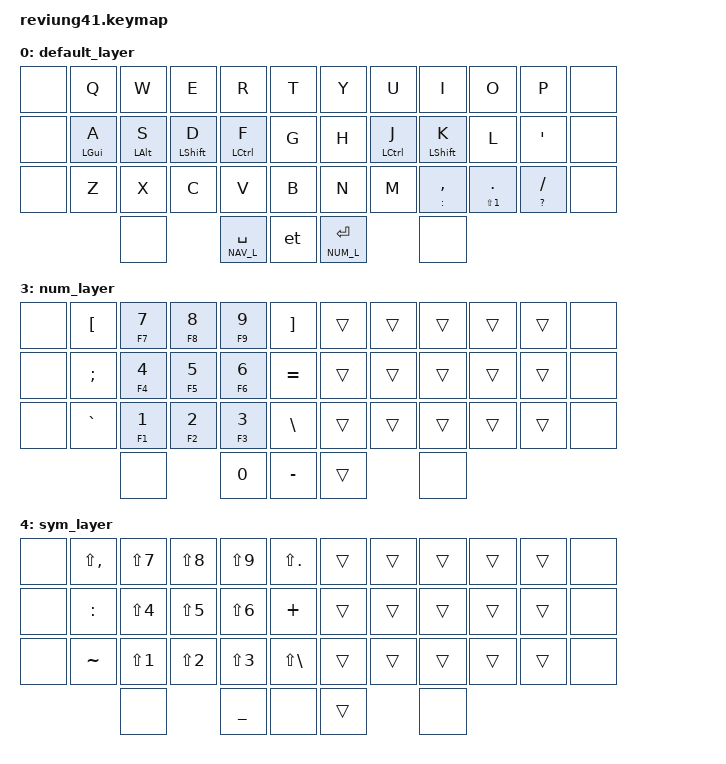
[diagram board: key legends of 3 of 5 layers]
/*
 * Copyright (c) 2020 The ZMK Contributors
 *
 * SPDX-License-Identifier: MIT
 */

#include <behaviors.dtsi>
#include <dt-bindings/zmk/keys.h>
#include <dt-bindings/zmk/bt.h>
#include <dt-bindings/zmk/rgb.h>

#define NAV_L 1
#define OTH_L 2
#define NUM_L 3
#define SYM_L 4
#define FUN_L 5

&lt { quick_tap_ms = <200>; };

/ {
    combos {
        compatible = "zmk,combos";
        combo_esc {
            timeout-ms = <50>;
            key-positions = <1 2>;
            bindings = <&kp ESC>;
        };    
        combo_lpar {
            timeout-ms = <50>;
            key-positions = <15 16>;
            layers = <0>;
            bindings = <&kp LPAR>;
        };  
        combo_rpar {
            timeout-ms = <50>;
            key-positions = <19 20>;
            layers = <0>;
            bindings = <&kp RPAR>;
        };  
        combo_rbrac {
            timeout-ms = <50>;
            key-positions = <19 20>;
            layers = <NUM_L>;
            bindings = <&mt RBRC RBKT>;
        }; 
        combo_lbrac {
            timeout-ms = <50>;
            key-positions = <15 16>;
            layers = <NUM_L>;
            bindings = <&mt LBRC LBKT>;
        };  
        combo_bspcup {
            timeout-ms = <50>;
            key-positions = <3 4>;
            layers = <NUM_L>;
            bindings = <&kp LC(DEL)>;
        };  
        combo_tab {
            timeout-ms = <50>;
            key-positions = <2 3>;
            bindings = <&kp TAB>;
        };  
        combo_bspchome {
            timeout-ms = <30>;
            key-positions = <14 16>;
            bindings = <&kp ESC>;
        };  

        combo_eql {
            timeout-ms = <50>;
            key-positions = <16 17>;
            bindings = <&kp PLUS>;
        }; 
        combo_plus {
            timeout-ms = <50>;
            key-positions = <18 19>;
            bindings = <&kp EQUAL>;
        }; 
        combo_bs_base {
            timeout-ms = <50>;
            key-positions = <7 8>;
            layers = <0>;
            bindings = <&kp BSPC>;
        };
        combo_bs_left {
            timeout-ms = <50>;
            key-positions = <7 8>;
            layers = <NAV_L>;
            bindings = <&kp LC(BSPC)>;
        }; 
        combo_bs {
            timeout-ms = <30>;
            key-positions = <8 9>;
            layers = <0>;
            bindings = <&kp BSPC>;
        }; 
        combo_minus {
            timeout-ms = <50>;
            key-positions = <14 15>;
            bindings = <&mt LS(MINUS) MINUS>;
        };  
        combo_underscore {
            timeout-ms = <50>;
            key-positions = <20 21>;
            bindings = <&kp UNDER>;
        };  
        combo_pipe {
            timeout-ms = <50>;
            key-positions = <28 29>;
            bindings = <&kp PIPE>;
        };  
        combo_bslash {
            timeout-ms = <50>;
            key-positions = <30 31>;
            bindings = <&kp BSLH>;
        };  
        combo_cut {
            timeout-ms = <50>;
            key-positions = <25 26>;
            bindings = <&kp LC(X)>;
        };  
        combo_copy {
            timeout-ms = <50>;
            key-positions = <26 27>;
            bindings = <&kp LC(C)>;
        };  
        combo_paste {
            timeout-ms = <50>;
            key-positions = <27 28>;
            bindings = <&mt LS(LC(V)) LC(V)>;
        }; 
    };
};

/ {
    behaviors {
        hm: homerow_mods {
            compatible = "zmk,behavior-hold-tap";
            label = "HOMEROW_MODS";
            #binding-cells = <2>;
            tapping-term-ms = <150>;
            quick_tap_ms = <0>;
            flavor = "tap-preferred";
            bindings = <&kp>, <&kp>;
        };
        et: escape-tab {
            compatible = "zmk,behavior-mod-morph";
            label = "escape-tab";
            #binding-cells = <0>;
            bindings = <&lt SYM_L BSPC>, <&kp TAB>;
            mods = <(MOD_LGUI|MOD_LSFT|MOD_LCTL|MOD_LALT)>;
        };
    };



    keymap {
        compatible = "zmk,keymap";

        default_layer {

// -------------------------------------------------------------------------------------
// |  XXX |  Q  |  W  |  E  |  R  |  T  |   |  Y  |  U   |  I  |  O  |  P  |   XXX    |
// |  XXX |  A  |  S  |  D  |  F  |  G  |   |  H  |  J   |  K  |  L  |  '  |   XXX    |
// |  XXX |  Z  |  X  |  C  |  V  |  B  |   |  N  |  M   |  ,  |  .  |  /  |   XXX    |
//                         | XXX | NAV | BSPC | NUM  | XXX |

                        bindings = <
   &none   &kp Q        &kp W        &kp E        &kp R        &kp T           &kp Y  &kp U        &kp I         &kp O   &kp P   &none
   &none   &hm LGUI A   &hm LALT S   &hm LSHIFT D &hm LCTRL F  &kp G           &kp H  &hm LCTRL J  &hm LSHIFT K  &kp L   &kp SQT &none
   &none   &kp Z        &kp X        &kp C        &kp V        &kp B           &kp N  &kp M        &mt COLON COMMA &mt LS(N1) DOT &mt QUESTION FSLH &none
                        &none                &lt NAV_L SPACE           &et        &lt NUM_L RET  &none
                        >;
                };

                nav_layer {

                         bindings = <
   &trans &trans  &trans &trans &trans &trans     &kp ESC  &kp BSPC &kp UP &mt LS(LC(V)) LC(V)  &kp PSCRN  &none
   &trans &trans  &trans &trans &trans &trans     &kp HOME &kp LEFT  &kp DOWN &kp RIGHT  &kp END &none
   &trans &trans  &trans &trans &trans &trans     &trans &kp LC(X) &kp LC(C)  &mt LS(LC(V)) LC(V) &none
                           &trans  &trans   &kp ESC   &lt OTH_L RET  &none
                        >;
                };


                other_layer {

                        bindings = <
   &none           &none           &none           &none           &none &none    &bt BT_SEL 0 &bt BT_SEL 1 &bt BT_SEL 2 &bt BT_SEL 3 &bt BT_CLR 
   &none           &none           &none           &none           &none &none              &none        &none        &none        &none        &none        &none
   &none           &none           &none           &none           &none &none              &reset       &none        &none        &none        &bootloader        &none
                                           &trans      &trans       &trans        &trans      &trans
                        >;
                };


                num_layer {
// -----------------------------------------------------------------------------------------
// |    |  1  |  2  |  3  |  4  |  5  |   |  6  |  7  |  8  |  9  |  0  | DEL |
// |    |  -  |  =  |  [  |  ]  |  \  |   | F1  | F2  | F3  | F4  | F5  | F6  |
// |    | ESC | GUI | ALT | CAPS|  "  |   | F7  | F8  | F9  | F10 | F11 | F12 |
//                       |     | ADJ | BKSP |    |     |
                        bindings = <
   &none &kp LBKT   &mt F7 N7  &mt F8 N8 &mt F9 N9  &kp RBKT              &trans    &trans   &trans    &trans   &trans   &none
   &none &kp SEMI   &mt F4 N4  &mt F5 N5 &mt F6 N6  &kp EQUAL             &trans    &trans   &trans    &trans   &trans   &none
   &none &kp GRAVE  &mt F1 N1  &mt F2 N2 &mt F3 N3  &kp BSLH              &trans    &trans   &trans    &trans   &trans   &none
                             &none       &kp N0     &kp MINUS  &trans      &none 
                        >;
                };

                sym_layer {
// -----------------------------------------------------------------------------------------
// |    |  1  |  2  |  3  |  4  |  5  |   |  6  |  7  |  8  |  9  |  0  | DEL |
// |    |  -  |  =  |  [  |  ]  |  \  |   | F1  | F2  | F3  | F4  | F5  | F6  |
// |    | ESC | GUI | ALT | CAPS|  "  |   | F7  | F8  | F9  | F10 | F11 | F12 |
//                       |     | ADJ | BKSP |    |     |
                        bindings = <
   &none  &kp LS(COMMA)   &kp LS(N7)  &kp LS(N8) &kp  LS(N9)  &kp LS(DOT)                 &trans    &trans   &trans    &trans   &trans   &none
   &none  &kp COLON  &kp LS(N4)  &kp LS(N5) &kp  LS(N6)  &kp PLUS                 &trans    &trans   &trans    &trans   &trans   &none
   &none  &kp TILDE  &kp LS(N1)  &kp LS(N2) &kp  LS(N3)  &kp LS(BSLH)             &trans    &trans   &trans    &trans   &trans   &none
                                   &none       &kp UNDER    &none  &trans      &none 
                        >;
                };

//                 sym_layer {

//                         bindings = <
//    &kp GRAVE &mt F1 N1  &mt F2 N2 &mt F3 N3 &mt F4 N4 &mt F5 N5        &mt F6 N6         &mt F7 N7    &mt F8 N8    &mt F9 N9    &mt F10 N0     &kp DEL
//    &kp TILDE &kp LS(N1)  &kp LS(N2) &kp LS(N3) &kp LS(N4) &kp LS(N5)        &kp LS(N6)         &kp LS(N7)    &mt F11 LS(N8)    &mt F12 LS(N9)   &mt F10 N0  &none
//    &trans &kp GRAVE &kp TILDE  &kp LBRC &kp LBKT  &trans       &trans &kp RBKT &kp RBRC   &trans &trans &trans
//                            &trans      &trans        &trans &trans  &trans 
//                         >;
//                 };

        };
};
